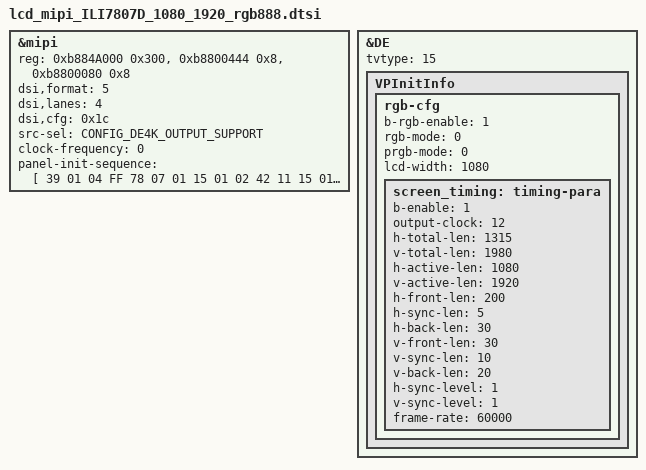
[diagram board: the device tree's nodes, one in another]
&mipi {
	reg = <0xb884A000 0x300>, <0xb8800444 0x8>,<0xb8800080 0x8>;

	/*
		* MIPI_COLOR_RGB565_0	=	0
		* MIPI_COLOR_RGB565_1	=	1
		* MIPI_COLOR_RGB565_2	=	2
		* MIPI_COLOR_RGB666_0	=	3
		* MIPI_COLOR_RGB666_1	=	4
		* MIPI_COLOR_RGB888	=	5
	*/
	dsi,format =<5>;

	dsi,lanes = <4>;

	/*
		* bit 6:5 MIPI_Virtual_Channel_Generic_ID
		* bit 4 :MIPI_CRC
		* bit 3 :MIPI_ECC
		* bit 2 :MIPI_Bus_Turn_request.
		* bit 1 :MIPI_EOTp
		* bit 0 :MIPI_EOTp
		*/

	dsi,cfg = <0x1c>;

	/*
		* 0: E_SRC_SEL_FXDE = 0
		* 1: E_SRC_SEL_4KDE
		* 2: E_SRC_SEL_HDMI_RX
		*/
	src-sel = <CONFIG_DE4K_OUTPUT_SUPPORT>;
	clock-frequency = <0>;
	// status = "okay";
};
&DE {
	tvtype = <15>;
	VPInitInfo {
		rgb-cfg{
			b-rgb-enable = <1>;
			/*
				* 0: MODE_PRGB
				* 1: MODE_SRGB
				*/
			rgb-mode = <0>;
			/*
				* 0: MODE_PRGB_888_10bit
				* 1: MODE_PRGB_666
				*/
			prgb-mode = <0>; 
			lcd-width = <1080>;
			screen_timing: timing-para {
				/* bool type, 0 or 1*/
				b-enable = <1>;
				/*
					* VPO_RGB_CLOCK_27M = 1,
					* VPO_RGB_CLOCK_33M = 2,
					* VPO_RGB_CLOCK_49M = 3,
					* VPO_RGB_CLOCK_66M = 4,
					* VPO_RGB_CLOCK_74M = 5,
					* VPO_RGB_CLOCK_85M = 6,
					* VPO_RGB_CLOCK_108M = 7,//H1600
					* VPO_RGB_CLOCK_6_6M = 8,
					* VPO_RGB_CLOCK_9M = 9,
					* VPO_RGB_CLOCK_39_6M = 10,
					* VPO_RGB_CLOCK_74_25M = 11,//H1600
					* VPO_RGB_CLOCK_148_5M = 12,//H1600
					* VPO_RGB_CLOCK_54M = 13,//H1600
					* VPO_RGB_CLOCK_132M = 14,//H1600
				*/
				output-clock = <12>;
				h-total-len = <1315>;
				v-total-len = <1980>;

				h-active-len = <1080>;
				v-active-len = <1920>;

				h-front-len = <200>;
				h-sync-len = <5>;
				h-back-len = <30>;

				v-front-len = <30>;
				v-sync-len = <10>;
				v-back-len = <20>;
				/* bool type, 0 or 1*/
				h-sync-level = <1>;
				/* bool type, 0 or 1*/
				v-sync-level = <1>;
				frame-rate = <60000>;
			};
		};
	};
};
&mipi{
panel-init-sequence = [
	39 01 04 FF 78 07 01
	15 01 02 42 11
	15 01 02 43 B2
	15 01 02 44 94
	15 01 02 4A 15
	15 01 02 4B 15
	15 01 02 50 73
	15 01 02 51 73
	15 01 02 5A 73
	15 01 02 A0 10
	15 01 02 A2 01
	15 01 02 A3 22
	15 01 02 B3 60
	15 01 02 B4 60
	39 01 04 FF 78 07 01
	15 01 02 22 06
	15 01 02 36 00
	15 01 02 60 0A
	15 01 02 64 08
	15 01 02 6C 45
	15 01 02 35 22
	15 01 02 24 02
	39 01 04 FF 78 07 07
	15 01 02 37 00
	15 01 02 12 22
	39 01 04 FF 78 07 08
	15 01 02 09 0e
	39 01 04 FF 78 07 06
	15 01 02 00 42
	15 01 02 01 04
	15 01 02 02 0B
	15 01 02 03 03
	15 01 02 04 00
	15 01 02 05 00
	15 01 02 06 00
	15 01 02 07 00
	15 01 02 08 81
	15 01 02 09 05
	15 01 02 0a 70
	15 01 02 0b 00
	15 01 02 0c 0B
	15 01 02 0d 0B
	15 01 02 0e 03
	15 01 02 0f 03
	15 01 02 10 00
	15 01 02 11 00
	15 01 02 12 00
	15 01 02 13 00
	15 01 02 14 00
	15 01 02 15 00
	15 01 02 31 22
	15 01 02 32 27
	15 01 02 33 07
	15 01 02 34 08
	15 01 02 35 10
	15 01 02 36 16
	15 01 02 37 14
	15 01 02 38 12
	15 01 02 39 07
	15 01 02 3a 07
	15 01 02 3b 07
	15 01 02 3c 28
	15 01 02 3d 29
	15 01 02 3e 2a
	15 01 02 3f 07
	15 01 02 40 07
	15 01 02 41 22
	15 01 02 42 27
	15 01 02 43 07
	15 01 02 44 09
	15 01 02 45 11
	15 01 02 46 17
	15 01 02 47 15
	15 01 02 48 13
	15 01 02 49 07
	15 01 02 4a 07
	15 01 02 4b 07
	15 01 02 4c 28
	15 01 02 4d 29
	15 01 02 4e 2a
	15 01 02 4f 07
	15 01 02 50 07
	15 01 02 61 22
	15 01 02 62 27
	15 01 02 63 07
	15 01 02 64 09
	15 01 02 65 13
	15 01 02 66 15
	15 01 02 67 17
	15 01 02 68 11
	15 01 02 69 07
	15 01 02 6a 07
	15 01 02 6b 07
	15 01 02 6c 28
	15 01 02 6d 29
	15 01 02 6e 2a
	15 01 02 6f 07
	15 01 02 70 07
	15 01 02 71 22
	15 01 02 72 27
	15 01 02 73 07
	15 01 02 74 08
	15 01 02 75 12
	15 01 02 76 14
	15 01 02 77 16
	15 01 02 78 10
	15 01 02 79 07
	15 01 02 7a 07
	15 01 02 7b 07
	15 01 02 7c 28
	15 01 02 7d 29
	15 01 02 7e 2a
	15 01 02 7f 07
	15 01 02 80 07
	15 01 02 d0 01
	15 01 02 db 40
	15 01 02 dc 04
	15 01 02 dd 00
	15 01 02 a0 13
	15 01 02 a1 00
	15 01 02 a2 05
	15 01 02 a3 20
	15 01 02 a6 00
	15 01 02 a7 00
	15 01 02 97 22
	15 01 02 D1 01
	15 01 02 D2 00
	15 01 02 DF 00
	15 01 02 E5 10
	15 01 02 E6 00
	15 01 02 D6 10
	15 01 02 D7 20
	15 01 02 D8 14
	15 01 02 D9 00
	15 01 02 DA 00
	15 01 02 B2 00
	15 01 02 B3 00
	39 01 04 FF 78 07 02
	15 01 02 00 00
	15 01 02 01 30
	15 01 02 02 00
	15 01 02 03 4A
	15 01 02 04 00
	15 01 02 05 6F
	15 01 02 06 00
	15 01 02 07 8B
	15 01 02 08 00
	15 01 02 09 A1
	15 01 02 0A 00
	15 01 02 0B B4
	15 01 02 0C 00
	15 01 02 0D C5
	15 01 02 0E 00
	15 01 02 0F D5
	15 01 02 10 00
	15 01 02 11 E2
	15 01 02 12 01
	15 01 02 13 10
	15 01 02 14 01
	15 01 02 15 34
	15 01 02 16 01
	15 01 02 17 6D
	15 01 02 18 01
	15 01 02 19 9A
	15 01 02 1A 01
	15 01 02 1B E2
	15 01 02 1C 02
	15 01 02 1D 1B
	15 01 02 1E 02
	15 01 02 1F 1C
	15 01 02 20 02
	15 01 02 21 52
	15 01 02 22 02
	15 01 02 23 8F
	15 01 02 24 02
	15 01 02 25 B7
	15 01 02 26 02
	15 01 02 27 EC
	15 01 02 28 03
	15 01 02 29 0E
	15 01 02 2A 03
	15 01 02 2B 3A
	15 01 02 2C 03
	15 01 02 2D 47
	15 01 02 2E 03
	15 01 02 2F 55
	15 01 02 30 03
	15 01 02 31 65
	15 01 02 32 03
	15 01 02 33 76
	15 01 02 34 03
	15 01 02 35 8A
	15 01 02 36 03
	15 01 02 37 A3
	15 01 02 38 03
	15 01 02 39 C4
	15 01 02 3A 03
	15 01 02 3B D1
	15 01 02 3C 00
	15 01 02 3D 30
	15 01 02 3E 00
	15 01 02 3F 4A
	15 01 02 40 00
	15 01 02 41 6F
	15 01 02 42 00
	15 01 02 43 8B
	15 01 02 44 00
	15 01 02 45 A1
	15 01 02 46 00
	15 01 02 47 B4
	15 01 02 48 00
	15 01 02 49 C5
	15 01 02 4A 00
	15 01 02 4B D5
	15 01 02 4C 00
	15 01 02 4D E2
	15 01 02 4E 01
	15 01 02 4F 10
	15 01 02 50 01
	15 01 02 51 34
	15 01 02 52 01
	15 01 02 53 6D
	15 01 02 54 01
	15 01 02 55 9A
	15 01 02 56 01
	15 01 02 57 E2
	15 01 02 58 02
	15 01 02 59 1B
	15 01 02 5A 02
	15 01 02 5B 1C
	15 01 02 5C 02
	15 01 02 5D 52
	15 01 02 5E 02
	15 01 02 5F 8F
	15 01 02 60 02
	15 01 02 61 B7
	15 01 02 62 02
	15 01 02 63 EC
	15 01 02 64 03
	15 01 02 65 0E
	15 01 02 66 03
	15 01 02 67 3A
	15 01 02 68 03
	15 01 02 69 47
	15 01 02 6A 03
	15 01 02 6B 55
	15 01 02 6C 03
	15 01 02 6D 65
	15 01 02 6E 03
	15 01 02 6F 76
	15 01 02 70 03
	15 01 02 71 8A
	15 01 02 72 03
	15 01 02 73 A3
	15 01 02 74 03
	15 01 02 75 C4
	15 01 02 76 03
	15 01 02 77 D1
	15 01 02 78 01
	15 01 02 79 01
	39 01 04 FF 78 07 03
	15 01 02 00 00
	15 01 02 01 30
	15 01 02 02 00
	15 01 02 03 4A
	15 01 02 04 00
	15 01 02 05 6F
	15 01 02 06 00
	15 01 02 07 8B
	15 01 02 08 00
	15 01 02 09 A1
	15 01 02 0A 00
	15 01 02 0B B4
	15 01 02 0C 00
	15 01 02 0D C5
	15 01 02 0E 00
	15 01 02 0F D5
	15 01 02 10 00
	15 01 02 11 E2
	15 01 02 12 01
	15 01 02 13 10
	15 01 02 14 01
	15 01 02 15 34
	15 01 02 16 01
	15 01 02 17 6D
	15 01 02 18 01
	15 01 02 19 9A
	15 01 02 1A 01
	15 01 02 1B E2
	15 01 02 1C 02
	15 01 02 1D 1B
	15 01 02 1E 02
	15 01 02 1F 1C
	15 01 02 20 02
	15 01 02 21 52
	15 01 02 22 02
	15 01 02 23 8F
	15 01 02 24 02
	15 01 02 25 B7
	15 01 02 26 02
	15 01 02 27 EC
	15 01 02 28 03
	15 01 02 29 0E
	15 01 02 2A 03
	15 01 02 2B 3A
	15 01 02 2C 03
	15 01 02 2D 47
	15 01 02 2E 03
	15 01 02 2F 55
	15 01 02 30 03
	15 01 02 31 65
	15 01 02 32 03
	15 01 02 33 76
	15 01 02 34 03
	15 01 02 35 8A
	15 01 02 36 03
	15 01 02 37 A3
	15 01 02 38 03
	15 01 02 39 C4
	15 01 02 3A 03
	15 01 02 3B D1
	15 01 02 3C 00
	15 01 02 3D 30
	15 01 02 3E 00
	15 01 02 3F 4A
	15 01 02 40 00
	15 01 02 41 6F
	15 01 02 42 00
	15 01 02 43 8B
	15 01 02 44 00
	15 01 02 45 A1
	15 01 02 46 00
	15 01 02 47 B4
	15 01 02 48 00
	15 01 02 49 C5
	15 01 02 4A 00
	15 01 02 4B D5
	15 01 02 4C 00
	15 01 02 4D E2
	15 01 02 4E 01
	15 01 02 4F 10
	15 01 02 50 01
	15 01 02 51 34
	15 01 02 52 01
	15 01 02 53 6D
	15 01 02 54 01
	15 01 02 55 9A
	15 01 02 56 01
	15 01 02 57 E2
	15 01 02 58 02
	15 01 02 59 1B
	15 01 02 5A 02
	15 01 02 5B 1C
	15 01 02 5C 02
	15 01 02 5D 52
	15 01 02 5E 02
	15 01 02 5F 8F
	15 01 02 60 02
	15 01 02 61 B7
	15 01 02 62 02
	15 01 02 63 EC
	15 01 02 64 03
	15 01 02 65 0E
	15 01 02 66 03
	15 01 02 67 3A
	15 01 02 68 03
	15 01 02 69 47
	15 01 02 6A 03
	15 01 02 6B 55
	15 01 02 6C 03
	15 01 02 6D 65
	15 01 02 6E 03
	15 01 02 6F 76
	15 01 02 70 03
	15 01 02 71 8A
	15 01 02 72 03
	15 01 02 73 A3
	15 01 02 74 03
	15 01 02 75 C4
	15 01 02 76 03
	15 01 02 77 D1
	15 01 02 78 01
	15 01 02 79 01
	39 01 04 FF 78 07 04
	15 01 02 00 00
	15 01 02 01 30
	15 01 02 02 00
	15 01 02 03 4A
	15 01 02 04 00
	15 01 02 05 6F
	15 01 02 06 00
	15 01 02 07 8B
	15 01 02 08 00
	15 01 02 09 A1
	15 01 02 0A 00
	15 01 02 0B B4
	15 01 02 0C 00
	15 01 02 0D C5
	15 01 02 0E 00
	15 01 02 0F D5
	15 01 02 10 00
	15 01 02 11 E2
	15 01 02 12 01
	15 01 02 13 10
	15 01 02 14 01
	15 01 02 15 34
	15 01 02 16 01
	15 01 02 17 6D
	15 01 02 18 01
	15 01 02 19 9A
	15 01 02 1A 01
	15 01 02 1B E2
	15 01 02 1C 02
	15 01 02 1D 1B
	15 01 02 1E 02
	15 01 02 1F 1C
	15 01 02 20 02
	15 01 02 21 52
	15 01 02 22 02
	15 01 02 23 8F
	15 01 02 24 02
	15 01 02 25 B7
	15 01 02 26 02
	15 01 02 27 EC
	15 01 02 28 03
	15 01 02 29 0E
	15 01 02 2A 03
	15 01 02 2B 3A
	15 01 02 2C 03
	15 01 02 2D 47
	15 01 02 2E 03
	15 01 02 2F 55
	15 01 02 30 03
	15 01 02 31 65
	15 01 02 32 03
	15 01 02 33 76
	15 01 02 34 03
	15 01 02 35 8A
	15 01 02 36 03
	15 01 02 37 A3
	15 01 02 38 03
	15 01 02 39 C4
	15 01 02 3A 03
	15 01 02 3B D1
	15 01 02 3C 00
	15 01 02 3D 30
	15 01 02 3E 00
	15 01 02 3F 4A
	15 01 02 40 00
	15 01 02 41 6F
	15 01 02 42 00
	15 01 02 43 8B
	15 01 02 44 00
	15 01 02 45 A1
	15 01 02 46 00
	15 01 02 47 B4
	15 01 02 48 00
	15 01 02 49 C5
	15 01 02 4A 00
	15 01 02 4B D5
	15 01 02 4C 00
	15 01 02 4D E2
	15 01 02 4E 01
	15 01 02 4F 10
	15 01 02 50 01
	15 01 02 51 34
	15 01 02 52 01
	15 01 02 53 6D
	15 01 02 54 01
	15 01 02 55 9A
	15 01 02 56 01
	15 01 02 57 E2
	15 01 02 58 02
	15 01 02 59 1B
	15 01 02 5A 02
	15 01 02 5B 1C
	15 01 02 5C 02
	15 01 02 5D 52
	15 01 02 5E 02
	15 01 02 5F 8F
	15 01 02 60 02
	15 01 02 61 B7
	15 01 02 62 02
	15 01 02 63 EC
	15 01 02 64 03
	15 01 02 65 0E
	15 01 02 66 03
	15 01 02 67 3A
	15 01 02 68 03
	15 01 02 69 47
	15 01 02 6A 03
	15 01 02 6B 55
	15 01 02 6C 03
	15 01 02 6D 65
	15 01 02 6E 03
	15 01 02 6F 76
	15 01 02 70 03
	15 01 02 71 8A
	15 01 02 72 03
	15 01 02 73 A3
	15 01 02 74 03
	15 01 02 75 C4
	15 01 02 76 03
	15 01 02 77 D1
	15 01 02 78 01
	15 01 02 79 01
	39 01 04 FF 78 07 00
	05 78 01 11
	05 78 01 29
	];
};
